# CEC1734_S0_2ZW register map
Vendor: Microchip Technology; Series: CEC; File version: 0
CPU: CM4 r1p0, little endian, MPU, FPU, 3 interrupt priority bits, 196 interrupts
Registers are 32-bit, read-write, reset 0x0 unless marked. A register's access mark holds for its fields unless they carry their own. Offsets are from the block's base; [hi:lo] are bit positions; lines under a group give offsets from that group; {n}, {i} and the like mark numbered series; 'fields as' and 'values as' point back to an identical list.

## UART0 — The 16550 UART is a full-function Two Pin Serial Port that supports the standard RS-232 Interface.
Base 0x4000C400; register names take the prefix UART_
0x00 DATA group — UART when DLAB=0
  0x00 RX_DAT 8-bit ro — UART Receive (Read) Buffer Register (DLAB=0)
  0x00 TX_DAT 8-bit wo — UART Transmit (Write) Buffer Register (DLAB=0)
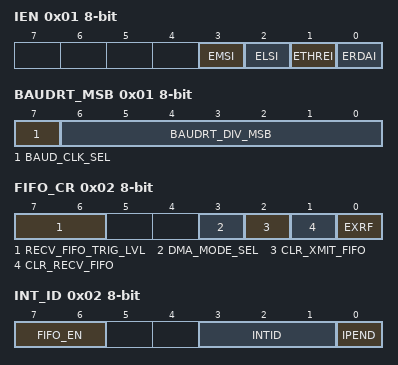
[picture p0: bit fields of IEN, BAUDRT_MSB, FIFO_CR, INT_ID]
  0x01 IEN 8-bit — UART Interrupt Enable Register (DLAB=0)
    [3] EMSI — EMSI This bit enables the MODEM Status Interrupt when set to logic '1'.
    [2] ELSI — ELSI This bit enables the Received Line Status Interrupt when set to logic '1'.
    [1] ETHREI — ETHREI This bit enables the Transmitter Holding Register Empty Interrupt when set to logic '1'.
    [0] ERDAI — ERDAI This bit enables the Received Data Available Interrupt (and timeout interrupts in the FIFO mode) when set to logic '1'.
  0x02 FIFO_CR 8-bit wo — UART FIFO Control Register
    [7:6] RECV_FIFO_TRIG_LVL — RECV_FIFO_TRIGGER_LEVEL These bits are used to set the trigger level for the RCVR FIFO interrupt.
    [3] DMA_MODE_SEL — DMA_MODE_SELECT Writing to this bit has no effect on the operation of the UART. The RXRDY and TXRDY pins are not available on this chip.
    [2] CLR_XMIT_FIFO — CLEAR_XMIT_FIFO Setting this bit to a logic '1' clears all bytes in the XMIT FIFO and resets its counter logic to '0' . The shift register is not cleared. This bit is self-clearing.
    [1] CLR_RECV_FIFO — CLEAR_RECV_FIFO Setting this bit to a logic '1' clears all bytes in the RCVR FIFO and resets its counter logic to '0'.
    [0] EXRF — EXRF Enable XMIT and RECV FIFO.
  0x02 INT_ID 8-bit ro — UART Interrupt Identification Register
    [7:6] FIFO_EN — These two bits are set when the FIFO CONTROL Register bit 0 equals 1.
    [3:1] INTID — INTID These bits identify the highest priority interrupt pending
    [0] IPEND — IPEND This bit can be used in either a hardwired prioritized or polled environment to indicate whether an interrupt is pending.
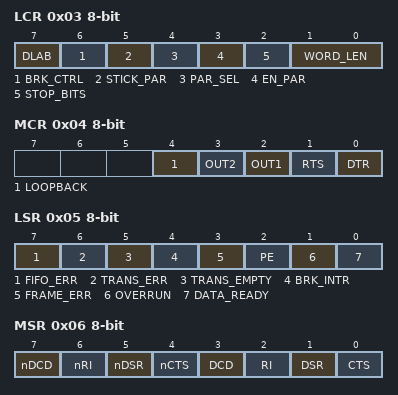
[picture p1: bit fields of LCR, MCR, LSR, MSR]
  0x03 LCR 8-bit — UART Line Control Register
    [7] DLAB — DLAB Divisor Latch Access Bit (DLAB).
    [6] BRK_CTRL — BREAK_CONTROL Set Break Control bit
    [5] STICK_PAR — STICK_PARITY Stick Parity bit.
    [4] PAR_SEL — PARITY_SELECT Even Parity Select bit.
      0=ODD (Odd Parity); 1=EVEN (Even Parity)
    [3] EN_PAR — ENABLE_PARITY Parity Enable bit.
    [2] STOP_BITS — STOP_BITS This bit specifies the number of stop bits in each transmitted or received serial character.
      0=ONE_STOP_BIT (1 Stop bit); 1=ONE_FIVE_TWO_STOP_BITS (1.5 or 2 Stop bits)
    [1:0] WORD_LEN — WORD_LENGTH These two bits specify the number of bits in each transmitted or received serial character.
      {v}={v+5}_BIT ({v+5} Bits) (v=0..3)
  0x04 MCR 8-bit — UART Modem Control Register
    [4] LOOPBACK — LOOPBACK This bit provides the loopback feature for diagnostic testing of the Serial Port.
    [3] OUT2 — OUT2 This bit is used to enable an UART interrupt.
    [2] OUT1 — OUT1 This bit controls the Output 1 (OUT1) bit.
    [1] RTS — RTS This bit controls the Request To Send (nRTS) output.
    [0] DTR — DTR This bit controls the Data Terminal Ready (nDTR) output.
  0x05 LSR 8-bit ro — UART Line Status Register
    [7] FIFO_ERR — FIFO_ERROR
    [6] TRANS_ERR — Transmitter Empty. Bit 6 is set to a logic '1' whenever the Transmitter Holding Register (THR) and Transmitter Shift Register (TSR) are both empty.
    [5] TRANS_EMPTY — TRANSMIT_EMPTY Transmitter Holding Register Empty Bit 5 indicates that the Serial Port is ready to accept a new character for transmission.
    [4] BRK_INTR — BREAK_INTERRUPT Break Interrupt.
    [3] FRAME_ERR — FRAME_ERROR Framing Error.
    [2] PE — PARITY ERROR Parity Error.
    [1] OVERRUN — OVERRUN Overrun Error.
    [0] DATA_READY — DATA_READY Data Ready. It is set to a logic '1' whenever a complete incoming character has been received and transferred into the Receiver Buffer Register or the FIFO
  0x06 MSR 8-bit ro — UART Modem Status Register
    [7] nDCD — nDCD This bit is the complement of the Data Carrier Detect (nDCD) input.
    [6] nRI — nRI This bit is the complement of the Ring Indicator (nRI) input.
    [5] nDSR — This bit is the complement of the Data Set Ready (nDSR) input.
    [4] nCTS — nCTS This bit is the complement of the Clear To Send (nCTS) input.
    [3] DCD — DCD Delta Data Carrier Detect (DDCD).
    [2] RI — RI Trailing Edge of Ring Indicator (TERI).
    [1] DSR — DSR Delta Data Set Ready (DDSR).
    [0] CTS — CTS Delta Clear To Send (DCTS).
  0x07 SCR 8-bit — UART Scratchpad Register This 8 bit read/write register has no effect on the operation of the Serial Port. It is intended as a scratchpad register to be used by the programmer to hold data temporarily.
  0x330 ACTIVATE 8-bit — UART Activate Register. [0:0] ACTIVATE When this bit is 1, the UART logical device is powered and functional. When this bit is 0, the UART logical device is powered down and inactive.
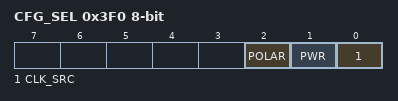
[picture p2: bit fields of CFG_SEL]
  0x3F0 CFG_SEL 8-bit — UART Config Select Register
    [2] POLAR — POLARITY 1=The UART_TX and UART_RX pins functions are inverted, 0=The UART_TX and UART_RX pins functions are not inverted
    [1] PWR — POWER 1=The RESET reset signal is derived from nSIO_RESET, 0=The RESET reset signal is derived from VCC1_RESET
    [0] CLK_SRC — CLK_SRC 1=The UART Baud Clock is derived from an external clock source, 0=The UART Baud Clock is derived from one of the two internal clock sources
      0=INTERNAL (Baud Clock is derived from one of the two internal clock sources); 1=EXTERNAL (Baud Clock is derived from an external clock source)
0x00 DLAB group (alternate view of DATA) — UART when DLAB=1
  0x00 BAUDRT_LSB 8-bit — UART Programmable BAUD Rate Generator (LSB) Register (DLAB=1)
  0x01 BAUDRT_MSB 8-bit — UART Programmable BAUD Rate Generator (MSB) Register (DLAB=1). [6:0] BAUD_RATE_DIVISOR_MSB, [7:7] BAUD_CLK_SEL 1=If CLK_SRC is '0', the baud clock is derived from the 1.8432MHz_Clk. If CLK_SRC is '1', this bit has no effect 0=If CLK_SRC is '0', the baud clock is derived from the 24MHz_Clk. If CLK_SRC is '1', this bit has no effect
    [7] BAUD_CLK_SEL — Baud Clock Selection
      0=1843200_Hz (Baud clock is derived from the 1.8432MHz Clk); 1=48000000_HZ (baud clock is derived from the 48MHz Clk)
    [6:0] BAUDRT_DIV_MSB — Baud Rate divisor (MSB).
  0x02 FIFO_CR 8-bit wo — UART FIFO Control Register
    fields as DATA.FIFO_CR
  0x02 INT_ID 8-bit ro — UART Interrupt Identification Register
    fields as DATA.INT_ID
  0x03 LCR 8-bit — UART Line Control Register
    fields as DATA.LCR
  0x04 MCR 8-bit — UART Modem Control Register
    fields as DATA.MCR
  0x05 LSR 8-bit ro — UART Line Status Register
    fields as DATA.LSR
  0x06 MSR 8-bit ro — UART Modem Status Register
    fields as DATA.MSR
  0x07 SCR 8-bit — UART Scratchpad Register This 8 bit read/write register has no effect on the operation of the Serial Port. It is intended as a scratchpad register to be used by the programmer to hold data temporarily.
  0x330 ACTIVATE 8-bit — UART Activate Register. [0:0] ACTIVATE When this bit is 1, the UART logical device is powered and functional. When this bit is 0, the UART logical device is powered down and inactive.
  0x3F0 CFG_SEL 8-bit — UART Config Select Register
    fields as DATA.CFG_SEL
